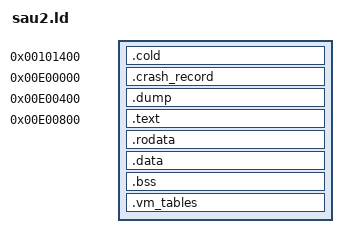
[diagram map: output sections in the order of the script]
/*
 * sau2.ld - the SAU2 domain_os kernel, laid out as the RFC load image that
 * sysboot loads and COLD_START maps (docs/rfc-cold-start.md, section 8)
 *
 * Generated by: Claude Opus 5.5 (rewritten for RFC step 3, source-yheb,
 * epic source-nqcs).
 *
 * The link produces an ELF (build/sau2/domain_os.elf, linked with
 * --emit-relocs); tools/gen_rfc_fixups.py turns it into the RFC file
 * dist/sau2/domain_os: the loadable sections by load address (LMA) from
 * file 0 = low address 0x101400, then the fixup table at RELOC.
 *
 * Addresses.  Every LMA here is the LOW address: where sysboot puts the
 * byte before the split (docs section 2), i.e. file offset + 0x101400, the
 * map's `loaded at'.  The file:
 *
 *   file    low       VMA          what
 *   0x000   0x101400  0x101400     .cold: RFC header (12 bytes), info block
 *                                  (24), COLD_START, its tables and stack
 *                                  (cold/sau2/cold_start.s, 0x800 bytes).
 *                                  VMA = LMA: COLD runs there, physically,
 *                                  before the MMU is on; its A5- and
 *                                  PC-relative cells and its `movea.l #COLD'
 *                                  are 0x101400-based.
 *   0x800   0x101C00  0xE00400     .dump: the DUMP page (dump/sau2/dump.s,
 *                                  0x400 bytes); COLD copies it to physical
 *                                  0x100C00 and maps it at its VMA.
 *   0xC00   0x102000  0xE00800     .text, .rodata, .data: the kernel, one
 *                                  stream, LMA = VMA - RFC_LOW_DELTA for
 *                                  every byte (holes included: they are
 *                                  zero bytes in the file); the first
 *                                  kernel page OS_PROC is page aligned.
 *   EOF-table  RELOC              the fixup table (count.w, then the low
 *                                  address of every 32-bit address cell),
 *                                  appended by gen_rfc_fixups.py; it is not
 *                                  a section of this link.
 *
 * Not in the file (NOBITS; `.vm_tables' past OS_PAGE_END is described
 * below):
 *   .crash_record  VMA OS_BEGIN 0xE00000: CRASH_$RECORD and
 *                  LOG_$LAST_ENTRY (log/log_data.c), the page COLD maps to
 *                  PPN 0x400, which survives a reboot (map `D41 E00000
 *                  CRASH_RECORD loaded at E00000').
 *   .bss           VMA RELOC up: first the room for the fixup table
 *                  (RELOC..RFC_FIXUP_TABLE_END, sized from the inputs'
 *                  R_68K_32 relocations), then the image's own bss, in map
 *                  order (build/sau2/layout_bss.ld).  The image let its
 *                  43 KB table overlay ACL_$DATA (at RELOC), which
 *                  ACL_$INIT zeroes; ours is larger than ACL_$DATA and
 *                  would reach RINGLOG_$DATA, XPD_$DATA and PROC2_$DATA, so
 *                  it gets RAM of its own.
 *
 * The bss rule (tools/gen_layout_ld.py, IMAGE_BSS_START): NOBITS is exactly
 * what the image had no file bytes for.  Zero-filled module data blocks
 * (`.bss.moddata.<name>') keyed in the image's bss (RELOC 0xE88834 up to
 * IODEFS_GUARD 0xF4FC00) and C bss objects defining a map symbol there go
 * to .bss (those keyed from AREA_$RPMAP_CACHE 0xEE4C00 up, only MST, to
 * .vm_tables instead), a page-aligned image address starting a page; every
 * other zero-filled block stays among the code as zeros in the file (as
 * the image had them), and every other C bss object is zeros in the file
 * at the end of .data (build/sau2/layout_data.ld).  So everything the image
 * had zeroed in its file is zeroed in ours, and the .bss part is what each
 * module's init zeroes itself in the image (ACL_$INIT ->
 * OS_$DATA_ZERO, ...; MMAP is cleared by COLD) - nothing clears it as a
 * whole (docs section 8.7).
 *
 * Symbols this script defines, read by COLD (cold/sau2/cold_start.s; they
 * were literals until source-m4xs) and named as in the map:
 *   OS_BEGIN     the bottom of the kernel's VAs, 0xE00000
 *   OS_PROC      the first kernel page, 0xE00800 (info block +8)
 *   OS_DATA      info block +4: the map's `.DATA' = OS_DATA_UNWIRED (the
 *                map has `D39 E78400 OS_DATA' there); nothing reads the
 *                cell (docs section 4), it is a fixup like the image's
 *   RELOC        the first byte after the last loaded byte: the fixup
 *                table's VMA, and the start of .bss
 *   OS_PAGE_END  the end of .bss rounded up to a page: COLD maps the kernel
 *                pages OS_PROC .. OS_PAGE_END
 * the VM tables' run-time windows (source-o7s2, docs section 8c), from
 * OS_PAGE_END up in the NOBITS `.vm_tables' (build/sau2/layout_vm.ld), at
 * the map's offsets, never mapped by COLD:
 *   AREA_$RPMAP_CACHE, MST (the C table), PIT_PAGES, MSTE_PAGES,
 *   VM_TABLES_END = IODEFS_GUARD
 * the boundaries OS_$INIT builds the address space from (source-wh9b;
 * os/os_internal.h has the table, docs section 8b the decisions), defined
 * by tools/gen_layout_ld.py at their map positions in layout.ld and
 * layout_bss.ld under the map's names:
 *   OS_DATA_WIRED     the first wired data (map 0xE1DC00, page aligned)
 *   OS_INIT_START, OS_INIT_END  the boot-only code and data that
 *                     os_$start_proc2 frees (map 0xE2F000, page aligned,
 *                     and 0xE35380)
 *   OS_PROC_UNWIRED   the start of the unwired code (map .TEXT 0xE38000,
 *                     32 KB aligned as in the image: OS_INIT_END rounded up)
 *   OS_DISK_PROC_END  the end of the disk code kept wired (map 0xE3E746;
 *                     its start is the function OS_DISK_PROC)
 *   OS_DATA_UNWIRED   the start of the unwired data (map .DATA = OS_DATA
 *                     0xE78400, page aligned; OS_DATA is defined equal to
 *                     it below, as in the map)
 *   OS_DISK_DATA, OS_DISK_DATA_END  the disk data kept wired (map 0xE784D0,
 *                     0xE7B044)
 *   OS_LINK_UNPLACED  ours, no map name: the catch-all code, .rodata and
 *                     .data, everything the map gives no position, which
 *                     OS_$INIT keeps wired up to RELOC
 *   OS_DATA_END       the end of the image's own bss blocks ACL_$DATA ..
 *                     PROC2_$DATA (map 0xEA9684)
 *   OS_PAGE           the stacks page OS_$STACK (map 0xEB0000, 32 KB
 *                     aligned: OS_$INIT rounds OS_DATA_END up to it)
 * and the constants of the physical split (docs section 2): the kernel
 * bytes below file page 0x55F stay at their low address, the rest are
 * loaded from PPN 0x600 (0x180000) up; COLD reaches MMAP, MMU_$PTTX and
 * P1_STACK_BASE through the high piece's formula, so they must lie at or
 * past OS_PROC + 0x55C00 (asserted below).
 *
 * Link order inside .text (source-0i3; the owner's decision of
 * 2026-09-28): the code and the module data blocks with file bytes are in
 * the order of the SAU2 link map (domain_os.10.2.map), not at the image's
 * addresses.  layout.ld is build/sau2/layout.ld, written before every link
 * by tools/gen_layout_ld.py (make passes -L build/sau2 so INCLUDE finds
 * it and its two siblings; none is checked in).  It lists one input-section
 * statement per C function (`.text.<symbol>', -ffunction-sections), per
 * hand-written routine (`.section ".text.<symbol>"') and per MODULE_DATA
 * block, in map order, and ends with the catch-all for code the map does
 * not name; ld assigns each input section to the first statement that
 * matches it, so the ordered list precedes the catch-all.  `make check'
 * links a scratch ELF and proves the order.
 *
 * The map order also gives the adjacencies that 16-bit and 8-bit
 * PC-relative references inside the image's hand-written segments need:
 *   SVC_CATCHER 0xE7B044: the eight trap dispatchers, then the nine
 *     dispatch tables (.text.svc_tables, anchored at 0xE7B2DE) reached with
 *     `lea (TABLE:w,%pc)' (source-a5t8);
 *   PROC1_ASM 0xE1EAC8: PROC1_$TSVV / PROC1_$CURRENT, EC_$WAIT .. ADVANCE /
 *     ADVANCE_INT, the PROC1 routines; `bsr.w' / `bsr.b' and `move.w
 *     (d,PC)' between them (source-uwxz, source-mc3k, source-0ke7);
 *   SIO_INT 0xE2DF80: SIO2681_$PTRS, then the two 2681 stubs (source-uwxz);
 *   SMD_WIRED 0xE26F20: SMD_$DISP1_INT, the cursor/scroll/BLT thunks,
 *     SMD_$DISPLAY_COM (C name SMD_DISPLAY_INFO, anchored) and SMD_TIME_$COM
 *     (source-uwxz, source-xlo9).
 *
 * Absolute image addresses still used as literals by C and hand-written
 * code (tools/check_guards.py's EXEMPT table, tools/asm_abs_addrs.md)
 * name memory this link gives to something else; they are tracked by
 * their beads.  OS_$INIT's layout boundaries come from the symbols above
 * since source-wh9b.
 */

OUTPUT_FORMAT("elf32-m68k")
OUTPUT_ARCH(m68k)
ENTRY(cold_start_entry)

/* The RFC load address: file byte 0 lands at physical 0x101400 (header
 * word 0); COLD's VMA. */
RFC_LOAD = 0x00101400;

/* VA - low address for DUMP and the kernel: the map's `loaded at' rule.
 * OS_PROC - RFC_LOW_DELTA = 0x102000 = RFC_LOAD + 0xC00, info block +0. */
RFC_LOW_DELTA = 0x00CFE800;

/* The physical split (info block +16 / +20, COLD's immediates): file pages
 * whose PPN would be >= 0x55F go to PPN 0x600 up. */
RFC_SPLIT_LOW = 0x00157C00;
RFC_KERNEL_LO_BYTES = 0x00055C00;   /* RFC_SPLIT_LOW - (OS_PROC - RFC_LOW_DELTA) */

OS_BEGIN = 0x00E00000;

/* The low region below the kernel (map `D92 D00000 OS_LOW' .. `D93 DA4800
 * OS_LOW_END_': UNWIRED_STACKS, DISK_BUFFERS, NETPOOL, AREA_PAGES), fixed
 * VAs not in the file; OS_$INIT maps them (canned map 1, 0x00E33996).
 * Symbols rather than C constants so the cells naming them are fixups, as
 * in the image (source-wh9b). */
OS_LOW = 0x00D00000;
OS_LOW_END = 0x00DA4800;

SECTIONS {
    .cold RFC_LOAD : AT(RFC_LOAD) {
        KEEP(*(".text.COLD"))
    }

    .crash_record OS_BEGIN (NOLOAD) : {
        KEEP(*(".bss.CRASH_$RECORD"))
        KEEP(*(".bss.LOG_$LAST_ENTRY"))
    }

    .dump OS_BEGIN + 0x400 : AT(OS_BEGIN + 0x400 - RFC_LOW_DELTA) {
        KEEP(*(".text.DUMP"))
    }

    .text OS_BEGIN + 0x800 : AT(OS_BEGIN + 0x800 - RFC_LOW_DELTA) {
        OS_PROC = .;
        INCLUDE layout.ld
    }

    .rodata : AT(ADDR(.rodata) - RFC_LOW_DELTA) {
        *(.rodata .rodata.*)
    }

    .data : AT(ADDR(.data) - RFC_LOW_DELTA) {
        *(.data .data.*)
        /* C bss objects the image had in its file: zero bytes */
        INCLUDE layout_data.ld
        . = ALIGN(4);
    }

    /* The last loaded byte + 1: the fixup table's VMA (its low address is
     * RELOC - RFC_LOW_DELTA, the end of the file before the table). */
    RELOC = ADDR(.data) + SIZEOF(.data);

    /* Info block +4 (cold_start.s): the map's OS_DATA is `.DATA' (`D21
     * E78400 .DATA' / `D39 E78400 OS_DATA'), the start of the unwired data,
     * which layout.ld defines as OS_DATA_UNWIRED; the same here, not the
     * start of the C .data section (source-wh9b review).  sysboot and COLD
     * never read the cell; it is a fixup, as in the image. */
    OS_DATA = OS_DATA_UNWIRED;

    .bss RELOC (NOLOAD) : {
        INCLUDE layout_bss.ld
    }

    OS_PAGE_END = ALIGN(ADDR(.bss) + SIZEOF(.bss), 0x400);

    /* The VM tables' run-time windows (docs/rfc-cold-start.md section 8c,
     * source-o7s2): the map's VM_TABLES from AREA_$RPMAP_CACHE (= its
     * AST_PMAPS_END) up to VM_TABLES_END = IODEFS_GUARD, at the map's
     * offsets (layout_vm.ld): AREA_$RPMAP_CACHE (3 pages, AREA_$INIT
     * 0x00E2F48A), MST (0xC00, MST_$INIT 0x00E30AE2), PIT_PAGES (0x40
     * pages, area_$alloc_seg_table 0x00E09D90), MSTE_PAGES (up to 0x166
     * pages, MST_$INIT / mst_$init_table_page 0x00E42D1A).  Virtual only:
     * not in the file and not mapped by COLD (it stops at OS_PAGE_END, as
     * the image's stops at its OS_PAGE_END 0xEC4800 below AUDIT_LIST /
     * AST_AOT / VM_TABLES); the kernel installs fresh pages at these VAs
     * unconditionally, so none of them may be a page COLD maps.  OS_$INIT's
     * canned map 5 covers them (OS_PAGE .. MSTE_PAGES + MST_PAGES_LIMIT
     * pages). */
    .vm_tables OS_PAGE_END (NOLOAD) : {
        INCLUDE layout_vm.ld
    }

    /* `D52 F4FC00 IODEFS_GUARD' = VM_TABLES_END: OS_$INIT's ceiling check
     * at 0x00E3397C (`move.l #IODEFS_GUARD,D0', a fixup cell). */
    IODEFS_GUARD = VM_TABLES_END;

    /* Discard debug sections and other unnecessary stuff */
    /DISCARD/ : {
        *(.comment)
        *(.note*)
        *(.eh_frame*)
        *(.debug*)
    }
}

/* docs/rfc-cold-start.md section 8 */
ASSERT(SIZEOF(.cold) == 0x800, "COLD must be 0x800 bytes: DUMP is at file 0x800")
ASSERT(SIZEOF(.crash_record) <= 0x400, "the crash record page is one page")
ASSERT(SIZEOF(.dump) == 0x400, "the DUMP page is 0x400 bytes at file 0x800")
ASSERT(OS_PROC == 0x00E00800, "the first kernel page is OS_BEGIN + 0x800")
ASSERT(OS_PROC - RFC_LOW_DELTA == RFC_LOAD + 0xC00, "the kernel starts at file 0xC00")
ASSERT(RELOC - RFC_LOW_DELTA > RFC_SPLIT_LOW, "the fixup table must start past the split (COLD traps otherwise)")
ASSERT(MMAP_$MMAPE >= OS_PROC + RFC_KERNEL_LO_BYTES && MMAP_$MMAPE < OS_PAGE_END, "MMAP must be in the high piece")
ASSERT(MMU_$PTTX >= OS_PROC + RFC_KERNEL_LO_BYTES && MMU_$PTTX < OS_PAGE_END, "MMU_$PTTX must be in the high piece")
ASSERT(OS_$STACK + 0x2000 >= OS_PROC + RFC_KERNEL_LO_BYTES && OS_$STACK + 0x2000 < OS_PAGE_END, "P1_STACK_BASE must be in the high piece")

/* OS_$INIT's address-space boundaries (os/os_internal.h, docs section 8b).
 * The two run-time roundings to a 32 KB segment must land where the image's
 * did: .TEXT's start rounded down is .TEXT's start (0x00E339A2), and
 * OS_DATA_END + 0x7FFF rounded down is OS_PAGE (0x00E339D6), so no wired
 * page is handed to the paging loop and the loop frees nothing past
 * OS_DATA_END that the kernel uses (stacks, MMAP, PTTX). */
ASSERT(OS_PROC_UNWIRED % 0x8000 == 0, "OS_PROC_UNWIRED must start a 32 KB segment")
ASSERT(OS_PAGE % 0x8000 == 0 && OS_PAGE == ALIGN(OS_DATA_END, 0x8000), "OS_PAGE must be OS_DATA_END rounded up to a 32 KB segment")
ASSERT(OS_PROC < OS_DATA_WIRED && OS_DATA_WIRED < OS_INIT_START && OS_INIT_START % 0x400 == 0 && OS_INIT_START < OS_INIT_END, "wired code, wired data, then the boot-only part")
ASSERT(OS_PROC_UNWIRED == ALIGN(OS_INIT_END, 0x8000), "os_$start_proc2 frees up to OS_INIT_END rounded to a segment, which must be .TEXT")
ASSERT(OS_PROC_UNWIRED <= OS_DISK_PROC && OS_DISK_PROC < OS_DISK_PROC_END && OS_DISK_PROC_END <= OS_DATA_UNWIRED, "OS_DISK_PROC..OS_DISK_PROC_END inside the unwired code")
ASSERT(OS_DATA_UNWIRED <= OS_DISK_DATA && OS_DISK_DATA <= OS_DISK_DATA_END && OS_DISK_DATA_END <= OS_LINK_UNPLACED, "OS_DISK_DATA..OS_DISK_DATA_END inside the unwired data")
ASSERT(OS_LINK_UNPLACED <= RELOC && RELOC <= OS_DATA_END && OS_DATA_END < OS_PAGE, "the unplaced part and the image's bss blocks below OS_DATA_END")
ASSERT(OS_$STACK == OS_PAGE && MMAP_$MMAPE >= OS_PAGE && MMU_$PTTX >= OS_PAGE, "the stacks, MMAP and PTTX lie past the paging loop")

/* The VM tables' run-time windows (docs section 8c, source-o7s2): right
 * after the COLD-mapped kernel, in the map's order and at its offsets,
 * page aligned, and below the I/O space.  AST_PMAPS_END (PMAP_$SEGMAP's end,
 * map size 0xFC00) is AREA_$RPMAP_CACHE as in the map.  The window end must
 * also stay below 0xFA0000, where COLD's 68020 fixup pass starts treating a
 * cell as an I/O address (cold_start.s IO_WINDOW, docs section 5 step 8),
 * and below DISP1_MEM = IODEFS 0xFC0000 (hardware, arch/m68k/sau2/
 * iodefs.s), which OS_$INIT compares IODEFS_GUARD with (0x00E33982). */
ASSERT(AREA_$RPMAP_CACHE == OS_PAGE_END && OS_PAGE_END % 0x400 == 0, "the VM-table windows start at OS_PAGE_END, on a page")
ASSERT(PMAP_$SEGMAP + 0xFC00 == AREA_$RPMAP_CACHE, "AST_PMAPS_END (PMAP_$SEGMAP + 0xFC00) must be AREA_$RPMAP_CACHE, the last COLD-mapped block")
ASSERT(AREA_$RPMAP_CACHE < MST && MST < PIT_PAGES && PIT_PAGES < MSTE_PAGES && MSTE_PAGES < VM_TABLES_END, "the VM-table windows in map order")
ASSERT(MST % 0x400 == 0 && PIT_PAGES % 0x400 == 0 && MSTE_PAGES % 0x400 == 0 && VM_TABLES_END % 0x400 == 0, "the VM-table windows start pages")
ASSERT(MST - AREA_$RPMAP_CACHE == 0xC00 && PIT_PAGES - MST == 0xC00 && MSTE_PAGES - PIT_PAGES == 0x10000, "the VM-table windows keep the map's sizes")
ASSERT(VM_TABLES_END == MSTE_PAGES + 0x166 * 0x400 && IODEFS_GUARD == VM_TABLES_END, "VM_TABLES_END = IODEFS_GUARD = MSTE_PAGES + MST_MSTE_PAGES_MAX pages")
ASSERT(VM_TABLES_END < 0x00FA0000 && VM_TABLES_END <= DISP1_MEM, "the VM tables must end below the 68020 I/O fixup window and IODEFS")
